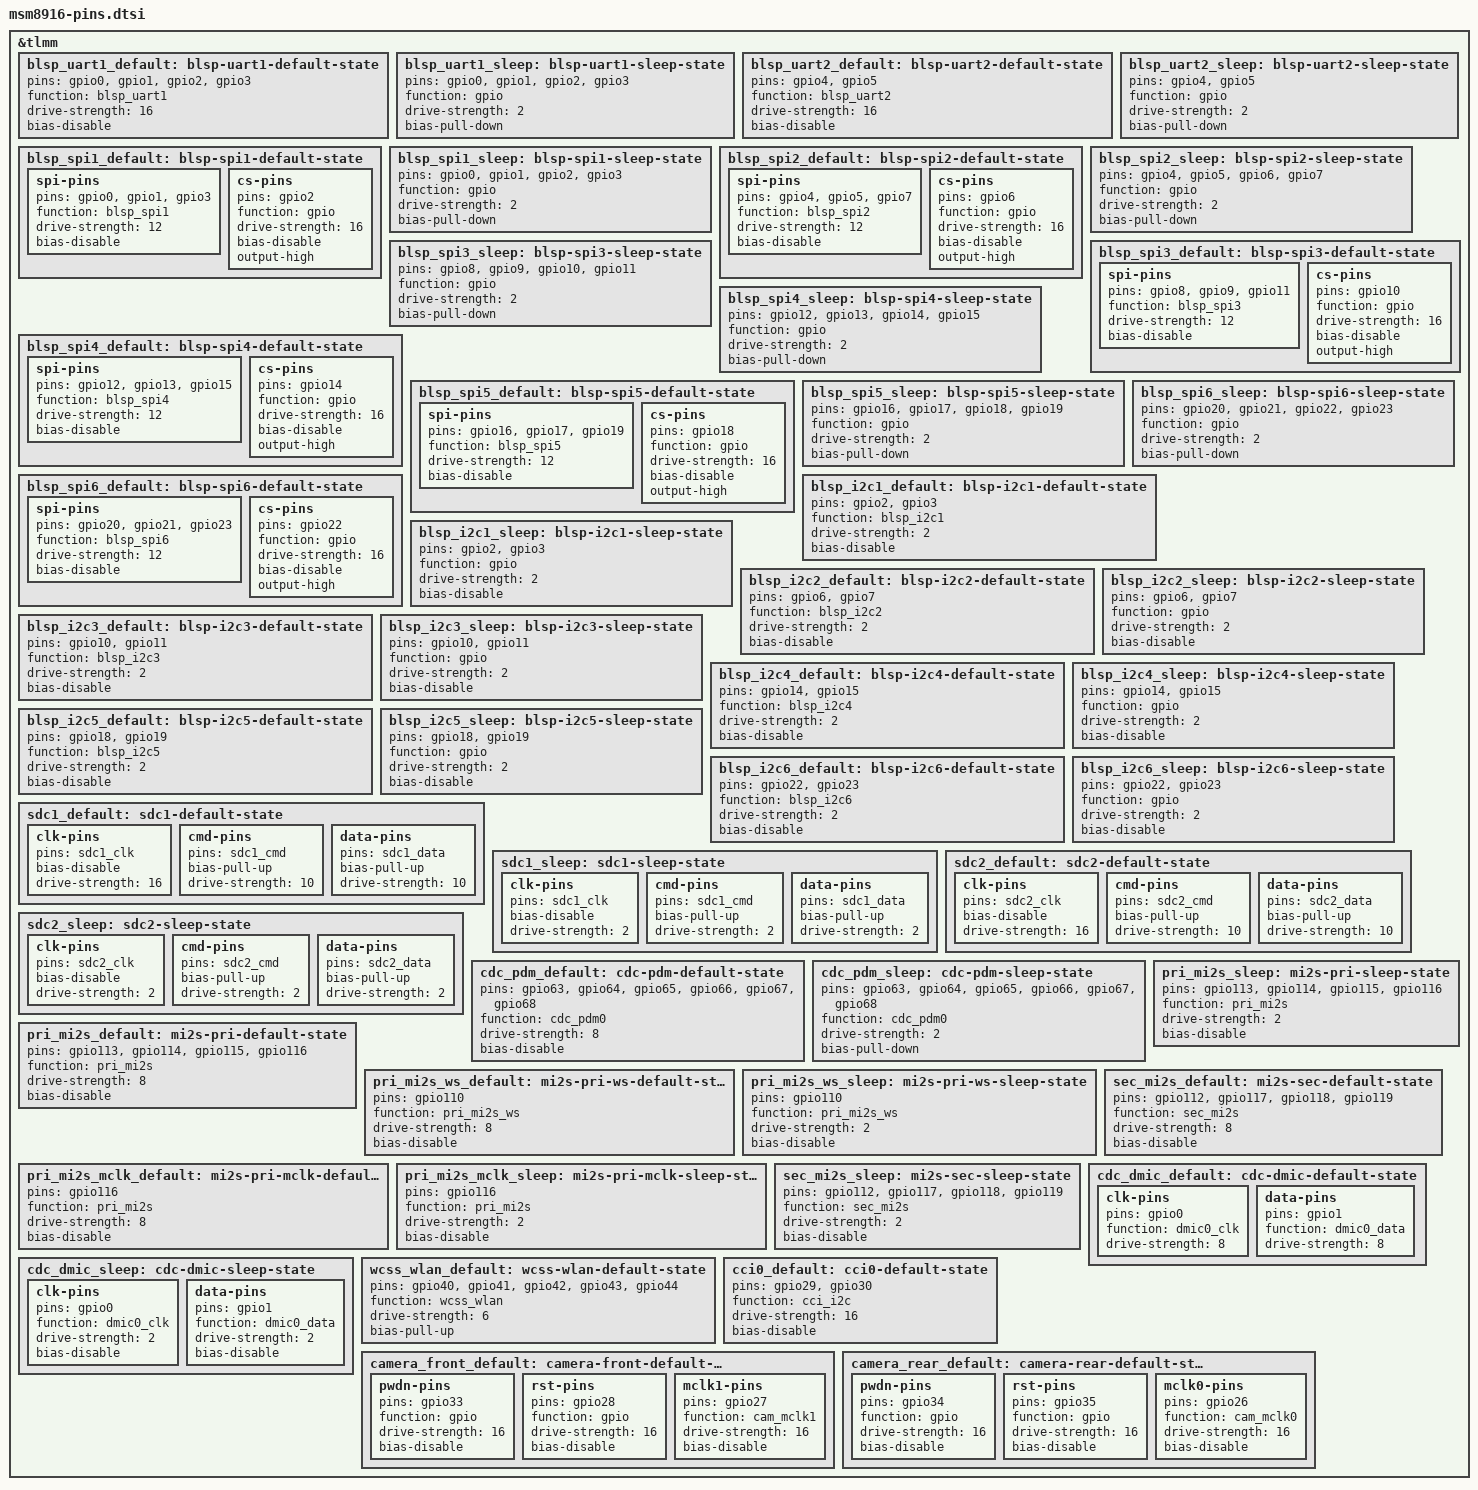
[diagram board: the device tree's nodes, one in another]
// SPDX-License-Identifier: GPL-2.0-only
/*
 * Copyright (c) 2013-2015, The Linux Foundation. All rights reserved.
 */

&tlmm {

	blsp_uart1_default: blsp-uart1-default-state {
		/* TX, RX, CTS_N, RTS_N */
		pins = "gpio0", "gpio1", "gpio2", "gpio3";
		function = "blsp_uart1";

		drive-strength = <16>;
		bias-disable;
	};

	blsp_uart1_sleep: blsp-uart1-sleep-state {
		pins = "gpio0", "gpio1", "gpio2", "gpio3";
		function = "gpio";

		drive-strength = <2>;
		bias-pull-down;
	};

	blsp_uart2_default: blsp-uart2-default-state {
		pins = "gpio4", "gpio5";
		function = "blsp_uart2";

		drive-strength = <16>;
		bias-disable;
	};

	blsp_uart2_sleep: blsp-uart2-sleep-state {
		pins = "gpio4", "gpio5";
		function = "gpio";

		drive-strength = <2>;
		bias-pull-down;
	};

	blsp_spi1_default: blsp-spi1-default-state {
		spi-pins {
			pins = "gpio0", "gpio1", "gpio3";
			function = "blsp_spi1";

			drive-strength = <12>;
			bias-disable;
		};
		cs-pins {
			pins = "gpio2";
			function = "gpio";

			drive-strength = <16>;
			bias-disable;
			output-high;
		};
	};

	blsp_spi1_sleep: blsp-spi1-sleep-state {
		pins = "gpio0", "gpio1", "gpio2", "gpio3";
		function = "gpio";

		drive-strength = <2>;
		bias-pull-down;
	};

	blsp_spi2_default: blsp-spi2-default-state {
		spi-pins {
			pins = "gpio4", "gpio5", "gpio7";
			function = "blsp_spi2";

			drive-strength = <12>;
			bias-disable;
		};
		cs-pins {
			pins = "gpio6";
			function = "gpio";

			drive-strength = <16>;
			bias-disable;
			output-high;
		};
	};

	blsp_spi2_sleep: blsp-spi2-sleep-state {
		pins = "gpio4", "gpio5", "gpio6", "gpio7";
		function = "gpio";

		drive-strength = <2>;
		bias-pull-down;
	};

	blsp_spi3_default: blsp-spi3-default-state {
		spi-pins {
			pins = "gpio8", "gpio9", "gpio11";
			function = "blsp_spi3";

			drive-strength = <12>;
			bias-disable;
		};
		cs-pins {
			pins = "gpio10";
			function = "gpio";

			drive-strength = <16>;
			bias-disable;
			output-high;
		};
	};

	blsp_spi3_sleep: blsp-spi3-sleep-state {
		pins = "gpio8", "gpio9", "gpio10", "gpio11";
		function = "gpio";

		drive-strength = <2>;
		bias-pull-down;
	};

	blsp_spi4_default: blsp-spi4-default-state {
		spi-pins {
			pins = "gpio12", "gpio13", "gpio15";
			function = "blsp_spi4";

			drive-strength = <12>;
			bias-disable;
		};
		cs-pins {
			pins = "gpio14";
			function = "gpio";

			drive-strength = <16>;
			bias-disable;
			output-high;
		};
	};

	blsp_spi4_sleep: blsp-spi4-sleep-state {
		pins = "gpio12", "gpio13", "gpio14", "gpio15";
		function = "gpio";

		drive-strength = <2>;
		bias-pull-down;
	};

	blsp_spi5_default: blsp-spi5-default-state {
		spi-pins {
			pins = "gpio16", "gpio17", "gpio19";
			function = "blsp_spi5";

			drive-strength = <12>;
			bias-disable;
		};
		cs-pins {
			pins = "gpio18";
			function = "gpio";

			drive-strength = <16>;
			bias-disable;
			output-high;
		};
	};

	blsp_spi5_sleep: blsp-spi5-sleep-state {
		pins = "gpio16", "gpio17", "gpio18", "gpio19";
		function = "gpio";

		drive-strength = <2>;
		bias-pull-down;
	};

	blsp_spi6_default: blsp-spi6-default-state {
		spi-pins {
			pins = "gpio20", "gpio21", "gpio23";
			function = "blsp_spi6";

			drive-strength = <12>;
			bias-disable;
		};
		cs-pins {
			pins = "gpio22";
			function = "gpio";

			drive-strength = <16>;
			bias-disable;
			output-high;
		};
	};

	blsp_spi6_sleep: blsp-spi6-sleep-state {
		pins = "gpio20", "gpio21", "gpio22", "gpio23";
		function = "gpio";

		drive-strength = <2>;
		bias-pull-down;
	};

	blsp_i2c1_default: blsp-i2c1-default-state {
		pins = "gpio2", "gpio3";
		function = "blsp_i2c1";

		drive-strength = <2>;
		bias-disable;
	};

	blsp_i2c1_sleep: blsp-i2c1-sleep-state {
		pins = "gpio2", "gpio3";
		function = "gpio";

		drive-strength = <2>;
		bias-disable;
	};

	blsp_i2c2_default: blsp-i2c2-default-state {
		pins = "gpio6", "gpio7";
		function = "blsp_i2c2";

		drive-strength = <2>;
		bias-disable;
	};

	blsp_i2c2_sleep: blsp-i2c2-sleep-state {
		pins = "gpio6", "gpio7";
		function = "gpio";

		drive-strength = <2>;
		bias-disable;
	};

	blsp_i2c3_default: blsp-i2c3-default-state {
		pins = "gpio10", "gpio11";
		function = "blsp_i2c3";

		drive-strength = <2>;
		bias-disable;
	};

	blsp_i2c3_sleep: blsp-i2c3-sleep-state {
		pins = "gpio10", "gpio11";
		function = "gpio";

		drive-strength = <2>;
		bias-disable;
	};

	blsp_i2c4_default: blsp-i2c4-default-state {
		pins = "gpio14", "gpio15";
		function = "blsp_i2c4";

		drive-strength = <2>;
		bias-disable;
	};

	blsp_i2c4_sleep: blsp-i2c4-sleep-state {
		pins = "gpio14", "gpio15";
		function = "gpio";

		drive-strength = <2>;
		bias-disable;
	};

	blsp_i2c5_default: blsp-i2c5-default-state {
		pins = "gpio18", "gpio19";
		function = "blsp_i2c5";

		drive-strength = <2>;
		bias-disable;
	};

	blsp_i2c5_sleep: blsp-i2c5-sleep-state {
		pins = "gpio18", "gpio19";
		function = "gpio";

		drive-strength = <2>;
		bias-disable;
	};

	blsp_i2c6_default: blsp-i2c6-default-state {
		pins = "gpio22", "gpio23";
		function = "blsp_i2c6";

		drive-strength = <2>;
		bias-disable;
	};

	blsp_i2c6_sleep: blsp-i2c6-sleep-state {
		pins = "gpio22", "gpio23";
		function = "gpio";

		drive-strength = <2>;
		bias-disable;
	};

	sdc1_default: sdc1-default-state {
		clk-pins {
			pins = "sdc1_clk";

			bias-disable;
			drive-strength = <16>;
		};
		cmd-pins {
			pins = "sdc1_cmd";

			bias-pull-up;
			drive-strength = <10>;
		};
		data-pins {
			pins = "sdc1_data";

			bias-pull-up;
			drive-strength = <10>;
		};
	};

	sdc1_sleep: sdc1-sleep-state {
		clk-pins {
			pins = "sdc1_clk";

			bias-disable;
			drive-strength = <2>;
		};
		cmd-pins {
			pins = "sdc1_cmd";

			bias-pull-up;
			drive-strength = <2>;
		};
		data-pins {
			pins = "sdc1_data";

			bias-pull-up;
			drive-strength = <2>;
		};
	};

	sdc2_default: sdc2-default-state {
		clk-pins {
			pins = "sdc2_clk";

			bias-disable;
			drive-strength = <16>;
		};
		cmd-pins {
			pins = "sdc2_cmd";

			bias-pull-up;
			drive-strength = <10>;
		};
		data-pins {
			pins = "sdc2_data";

			bias-pull-up;
			drive-strength = <10>;
		};
	};

	sdc2_sleep: sdc2-sleep-state {
		clk-pins {
			pins = "sdc2_clk";

			bias-disable;
			drive-strength = <2>;
		};
		cmd-pins {
			pins = "sdc2_cmd";

			bias-pull-up;
			drive-strength = <2>;
		};
		data-pins {
			pins = "sdc2_data";

			bias-pull-up;
			drive-strength = <2>;
		};
	};

	cdc_pdm_default: cdc-pdm-default-state {
		pins = "gpio63", "gpio64", "gpio65", "gpio66",
		       "gpio67", "gpio68";
		function = "cdc_pdm0";

		drive-strength = <8>;
		bias-disable;
	};

	cdc_pdm_sleep: cdc-pdm-sleep-state {
		pins = "gpio63", "gpio64", "gpio65", "gpio66",
		       "gpio67", "gpio68";
		function = "cdc_pdm0";

		drive-strength = <2>;
		bias-pull-down;
	};

	pri_mi2s_default: mi2s-pri-default-state {
		pins = "gpio113", "gpio114", "gpio115", "gpio116";
		function = "pri_mi2s";

		drive-strength = <8>;
		bias-disable;
	};

	pri_mi2s_sleep: mi2s-pri-sleep-state {
		pins = "gpio113", "gpio114", "gpio115", "gpio116";
		function = "pri_mi2s";

		drive-strength = <2>;
		bias-disable;
	};

	pri_mi2s_ws_default: mi2s-pri-ws-default-state {
		pins = "gpio110";
		function = "pri_mi2s_ws";

		drive-strength = <8>;
		bias-disable;
	};

	pri_mi2s_ws_sleep: mi2s-pri-ws-sleep-state {
		pins = "gpio110";
		function = "pri_mi2s_ws";

		drive-strength = <2>;
		bias-disable;
	};

	pri_mi2s_mclk_default: mi2s-pri-mclk-default-state {
		pins = "gpio116";
		function = "pri_mi2s";

		drive-strength = <8>;
		bias-disable;
	};

	pri_mi2s_mclk_sleep: mi2s-pri-mclk-sleep-state {
		pins = "gpio116";
		function = "pri_mi2s";

		drive-strength = <2>;
		bias-disable;
	};

	sec_mi2s_default: mi2s-sec-default-state {
		pins = "gpio112", "gpio117", "gpio118", "gpio119";
		function = "sec_mi2s";

		drive-strength = <8>;
		bias-disable;
	};

	sec_mi2s_sleep: mi2s-sec-sleep-state {
		pins = "gpio112", "gpio117", "gpio118", "gpio119";
		function = "sec_mi2s";

		drive-strength = <2>;
		bias-disable;
	};

	cdc_dmic_default: cdc-dmic-default-state {
		clk-pins {
			pins = "gpio0";
			function = "dmic0_clk";

			drive-strength = <8>;
		};
		data-pins {
			pins = "gpio1";
			function = "dmic0_data";

			drive-strength = <8>;
		};
	};

	cdc_dmic_sleep: cdc-dmic-sleep-state {
		clk-pins {
			pins = "gpio0";
			function = "dmic0_clk";

			drive-strength = <2>;
			bias-disable;
		};
		data-pins {
			pins = "gpio1";
			function = "dmic0_data";

			drive-strength = <2>;
			bias-disable;
		};
	};

	wcss_wlan_default: wcss-wlan-default-state {
		pins = "gpio40", "gpio41", "gpio42", "gpio43", "gpio44";
		function = "wcss_wlan";

		drive-strength = <6>;
		bias-pull-up;
	};

	cci0_default: cci0-default-state {
		pins = "gpio29", "gpio30";
		function = "cci_i2c";

		drive-strength = <16>;
		bias-disable;
	};

	camera_front_default: camera-front-default-state {
		pwdn-pins {
			pins = "gpio33";
			function = "gpio";

			drive-strength = <16>;
			bias-disable;
		};
		rst-pins {
			pins = "gpio28";
			function = "gpio";

			drive-strength = <16>;
			bias-disable;
		};
		mclk1-pins {
			pins = "gpio27";
			function = "cam_mclk1";

			drive-strength = <16>;
			bias-disable;
		};
	};

	camera_rear_default: camera-rear-default-state {
		pwdn-pins {
			pins = "gpio34";
			function = "gpio";

			drive-strength = <16>;
			bias-disable;
		};
		rst-pins {
			pins = "gpio35";
			function = "gpio";

			drive-strength = <16>;
			bias-disable;
		};
		mclk0-pins {
			pins = "gpio26";
			function = "cam_mclk0";

			drive-strength = <16>;
			bias-disable;
		};
	};
};
